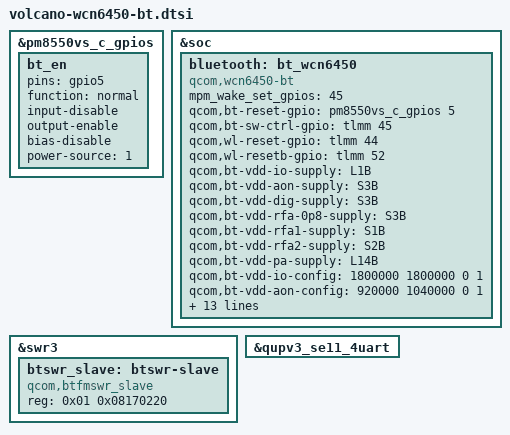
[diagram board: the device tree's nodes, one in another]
#include <dt-bindings/interconnect/qcom,volcano.h>


&pm8550vs_c_gpios {
	bt_en: bt_en {
		pins = "gpio5";
		function = "normal";
		input-disable;
		output-enable;
		bias-disable;
		power-source = <1>;
	};
};

&soc {
	bluetooth: bt_wcn6450 {
		compatible = "qcom,wcn6450-bt";
		/* List of GPIOs to be setup for interrupt wakeup capable*/
		mpm_wake_set_gpios = <45>;
		qcom,bt-reset-gpio = <&pm8550vs_c_gpios 5 0>; /* BT_EN */
		qcom,bt-sw-ctrl-gpio = <&tlmm 45 0>; /* SW_CTRL */
		qcom,wl-reset-gpio = <&tlmm 44 0>; /* WL_EN */
		qcom,wl-resetb-gpio = <&tlmm 52 0>; /* RESETB */

		qcom,bt-vdd-io-supply = <&L1B>;       /* IO */
		qcom,bt-vdd-aon-supply = <&S3B>;      /* AON */
		qcom,bt-vdd-dig-supply = <&S3B>;      /* BT_CX_MX */
		qcom,bt-vdd-rfa-0p8-supply = <&S3B>;   /* RFA 0p8 */
		qcom,bt-vdd-rfa1-supply = <&S1B>;     /* RFA 1p8 */
		qcom,bt-vdd-rfa2-supply = <&S2B>;     /* RFA 1p2 */
		qcom,bt-vdd-pa-supply = <&L14B>;   /* WLBT 3p3 2g*/

		/* max voltage are set to regulator max voltage supported */
		qcom,bt-vdd-io-config = <1800000 1800000 0 1>;
		qcom,bt-vdd-aon-config = <920000 1040000 0 1>;
		qcom,bt-vdd-dig-config  = <920000 1040000 0 1>;
		qcom,bt-vdd-rfa-0p8-config = <920000 1040000 0 1>;
		qcom,bt-vdd-rfa1-config = <1856000 2080000 0 1>;
		qcom,bt-vdd-rfa2-config = <1256000 1408000 0 1>;
		qcom,bt-vdd-pa-config = <3125000 3125000 0 1>;

		qcom,pdc_init_table =
			" {class: wlan_pdc, ss: rf, res: s3b.v, dwnval: 920}",
			" {class: wlan_pdc, ss: rf, res: s1b.v, dwnval: 1856}",
			" {class: wlan_pdc, ss: rf, res: s3b.v, upval: 1040}",
			" {class: wlan_pdc, ss: rf, res: s1b.v, upval: 2040}",
			" {class: wlan_pdc, ss: rf, res: s2b.v, upval: 1408}",
			" {class: wlan_pdc, ss: rf, res: g1f.e, enable: 0}",
			" {class: wlan_pdc, ss: rf, res: l1b.m, enable: 1}";
	};
};

&swr3 {
	btswr_slave: btswr-slave {
		compatible = "qcom,btfmswr_slave";
		reg = <0x01 0x08170220>;
	};
};

//uart instance
&qupv3_se11_4uart {
	status = "ok";
};
